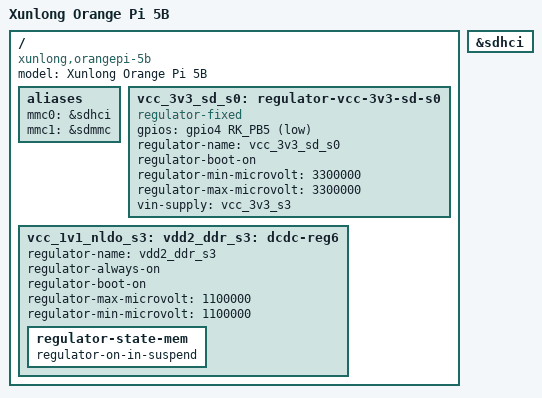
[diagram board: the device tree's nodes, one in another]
// SPDX-License-Identifier: (GPL-2.0+ OR MIT)

/dts-v1/;

#include "rk3588s-orangepi-5.dtsi"

/ {
	model = "Xunlong Orange Pi 5B";
	compatible = "xunlong,orangepi-5b", "rockchip,rk3588s";

	aliases {
		mmc0 = &sdhci;
		mmc1 = &sdmmc;
	};

	vcc_3v3_sd_s0: regulator-vcc-3v3-sd-s0 {
		compatible = "regulator-fixed";
		gpios = <&gpio4 RK_PB5 GPIO_ACTIVE_LOW>;
		regulator-name = "vcc_3v3_sd_s0";
		regulator-boot-on;
		regulator-min-microvolt = <3300000>;
		regulator-max-microvolt = <3300000>;
		vin-supply = <&vcc_3v3_s3>;
	};

	vcc_1v1_nldo_s3: vdd2_ddr_s3: dcdc-reg6 {
		regulator-name = "vdd2_ddr_s3";
		regulator-always-on;
		regulator-boot-on;
		regulator-max-microvolt = <1100000>;
		regulator-min-microvolt = <1100000>;

		regulator-state-mem {
			regulator-on-in-suspend;
		};
	};
};

&sdhci {
	status = "okay";
};
